# PIC32CX2051MTSH128S1 device description
Architecture: CORTEX-M4; Family: PIC32CXMT; Series: PIC32CXMTSH
Registers are 32-bit, read-write, no defined reset value unless marked. A register's access mark holds for its fields unless they carry their own. Offsets are from the block's base; [hi:lo] are bit positions; lines under a group give offsets from that group; {n}, {i} and the like mark numbered series; 'fields as' and 'values as' point back to an identical list.

## PWM — Pulse Width Modulation Controller
Instances: PWM 0x4801C000
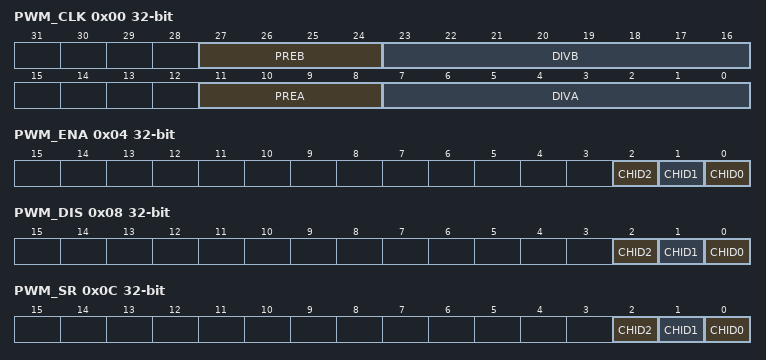
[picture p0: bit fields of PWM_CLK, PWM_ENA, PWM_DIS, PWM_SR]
0x00 PWM_CLK — PWM Clock Register
  [27:24] PREB — CLKB Source Clock Selection
    0=CLK (Peripheral clock); 1=CLK_DIV2 (Peripheral clock/2); 2=CLK_DIV4 (Peripheral clock/4); 3=CLK_DIV8 (Peripheral clock/8); 4=CLK_DIV16 (Peripheral clock/16); 5=CLK_DIV32 (Peripheral clock/32); 6=CLK_DIV64 (Peripheral clock/64); 7=CLK_DIV128 (Peripheral clock/128); 8=CLK_DIV256 (Peripheral clock/256); 9=CLK_DIV512 (Peripheral clock/512); 10=CLK_DIV1024 (Peripheral clock/1024)
  [23:16] DIVB — CLKB Divide Factor
    0=CLKB_POFF (CLKB clock is turned off); 1=PREB (CLKB clock is clock selected by PREB)
  [11:8] PREA — CLKA Source Clock Selection
    values as PREB
  [7:0] DIVA — CLKA Divide Factor
    0=CLKA_POFF (CLKA clock is turned off); 1=PREA (CLKA clock is clock selected by PREA)
0x04 PWM_ENA wo — PWM Enable Register
  [2] CHID2 — Channel ID
  [1] CHID1 — Channel ID
  [0] CHID0 — Channel ID
0x08 PWM_DIS wo — PWM Disable Register
  fields as PWM_ENA
0x0C PWM_SR ro — PWM Status Register
  fields as PWM_ENA
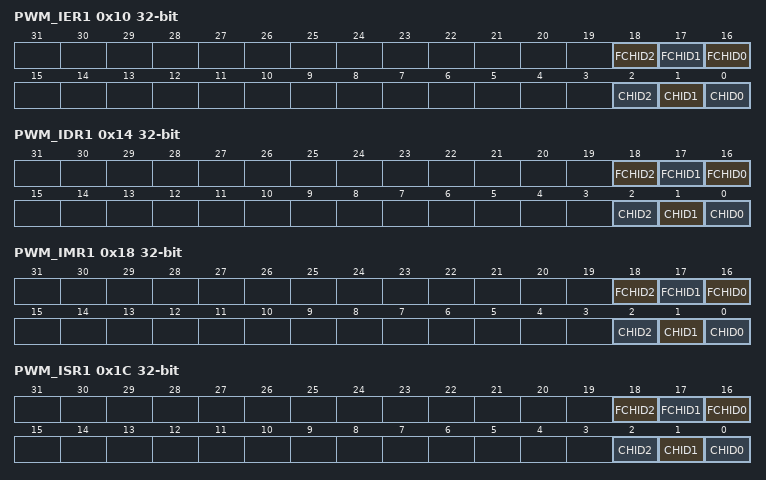
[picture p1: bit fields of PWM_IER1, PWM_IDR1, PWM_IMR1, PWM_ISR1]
0x10 PWM_IER1 wo — PWM Interrupt Enable Register 1
  [18] FCHID2 — Fault Protection Trigger on Channel 2 Interrupt Enable
  [17] FCHID1 — Fault Protection Trigger on Channel 1 Interrupt Enable
  [16] FCHID0 — Fault Protection Trigger on Channel 0 Interrupt Enable
  [2] CHID2 — Counter Event on Channel 2 Interrupt Enable
  [1] CHID1 — Counter Event on Channel 1 Interrupt Enable
  [0] CHID0 — Counter Event on Channel 0 Interrupt Enable
0x14 PWM_IDR1 wo — PWM Interrupt Disable Register 1
  [18] FCHID2 — Fault Protection Trigger on Channel 2 Interrupt Disable
  [17] FCHID1 — Fault Protection Trigger on Channel 1 Interrupt Disable
  [16] FCHID0 — Fault Protection Trigger on Channel 0 Interrupt Disable
  [2] CHID2 — Counter Event on Channel 2 Interrupt Disable
  [1] CHID1 — Counter Event on Channel 1 Interrupt Disable
  [0] CHID0 — Counter Event on Channel 0 Interrupt Disable
0x18 PWM_IMR1 ro — PWM Interrupt Mask Register 1
  [18] FCHID2 — Fault Protection Trigger on Channel 2 Interrupt Mask
  [17] FCHID1 — Fault Protection Trigger on Channel 1 Interrupt Mask
  [16] FCHID0 — Fault Protection Trigger on Channel 0 Interrupt Mask
  [2] CHID2 — Counter Event on Channel 2 Interrupt Mask
  [1] CHID1 — Counter Event on Channel 1 Interrupt Mask
  [0] CHID0 — Counter Event on Channel 0 Interrupt Mask
0x1C PWM_ISR1 ro — PWM Interrupt Status Register 1
  [18] FCHID2 — Fault Protection Trigger on Channel 2
  [17] FCHID1 — Fault Protection Trigger on Channel 1
  [16] FCHID0 — Fault Protection Trigger on Channel 0
  [2] CHID2 — Counter Event on Channel 2
  [1] CHID1 — Counter Event on Channel 1
  [0] CHID0 — Counter Event on Channel 0
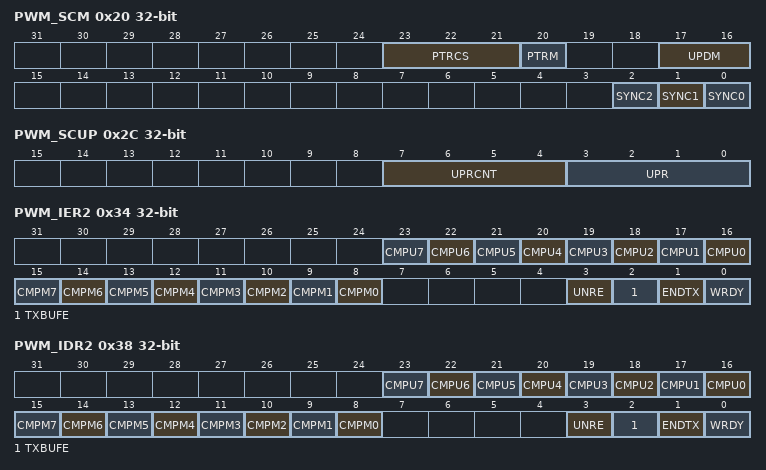
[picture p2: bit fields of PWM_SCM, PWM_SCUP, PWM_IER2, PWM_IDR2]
0x20 PWM_SCM — PWM Sync Channels Mode Register
  [23:21] PTRCS — Peripheral DMA Controller Transfer Request Comparison Selection
  [20] PTRM — Peripheral DMA Controller Transfer Request Mode
  [17:16] UPDM — Synchronous Channels Update Mode
    0=MODE0 (Manual write of double buffer registers and manual update of synchronous channels); 1=MODE1 (Manual write of double buffer registers and automatic update of synchronous channels); 2=MODE2 (Automatic write of duty-cycle update registers by the Peripheral DMA Controller and automatic update of synchronous channels)
  [2] SYNC2 — Synchronous Channel 2
  [1] SYNC1 — Synchronous Channel 1
  [0] SYNC0 — Synchronous Channel 0
0x28 PWM_SCUC — PWM Sync Channels Update Control Register
  [0] UPDULOCK — Synchronous Channels Update Unlock
0x2C PWM_SCUP — PWM Sync Channels Update Period Register
  [7:4] UPRCNT — Update Period Counter
  [3:0] UPR — Update Period
0x30 PWM_SCUPUPD wo — PWM Sync Channels Update Period Update Register
  [3:0] UPRUPD — Update Period Update
0x34 PWM_IER2 wo — PWM Interrupt Enable Register 2
  [n+16] CMPU{n} (n=0..7) — Comparison {n} Update Interrupt Enable
  [n+8] CMPM{n} (n=0..7) — Comparison {n} Match Interrupt Enable
  [3] UNRE — Synchronous Channels Update Underrun Error Interrupt Enable
  [2] TXBUFE — PDC TX Buffer Empty Interrupt Enable
  [1] ENDTX — PDC End of TX Buffer Interrupt Enable
  [0] WRDY — Write Ready for Synchronous Channels Update Interrupt Enable
0x38 PWM_IDR2 wo — PWM Interrupt Disable Register 2
  [n+16] CMPU{n} (n=0..7) — Comparison {n} Update Interrupt Disable
  [n+8] CMPM{n} (n=0..7) — Comparison {n} Match Interrupt Disable
  [3] UNRE — Synchronous Channels Update Underrun Error Interrupt Disable
  [2] TXBUFE — PDC TX Buffer Empty Interrupt Disable
  [1] ENDTX — PDC End of TX Buffer Interrupt Disable
  [0] WRDY — Write Ready for Synchronous Channels Update Interrupt Disable
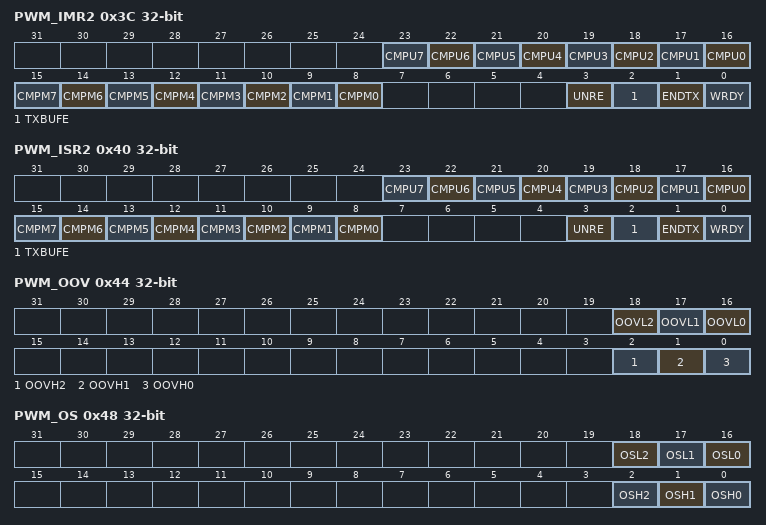
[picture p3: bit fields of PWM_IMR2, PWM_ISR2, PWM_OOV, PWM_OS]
0x3C PWM_IMR2 ro — PWM Interrupt Mask Register 2
  [n+16] CMPU{n} (n=0..7) — Comparison {n} Update Interrupt Mask
  [n+8] CMPM{n} (n=0..7) — Comparison {n} Match Interrupt Mask
  [3] UNRE — Synchronous Channels Update Underrun Error Interrupt Mask
  [2] TXBUFE — PDC TX Buffer Empty Interrupt Mask
  [1] ENDTX — PDC End of TX Buffer Interrupt Mask
  [0] WRDY — Write Ready for Synchronous Channels Update Interrupt Mask
0x40 PWM_ISR2 ro — PWM Interrupt Status Register 2
  [n+16] CMPU{n} (n=0..7) — Comparison {n} Update
  [n+8] CMPM{n} (n=0..7) — Comparison {n} Match
  [3] UNRE — Synchronous Channels Update Underrun Error
  [2] TXBUFE — PDC TX Buffer Empty
  [1] ENDTX — PDC End of TX Buffer
  [0] WRDY — Write Ready for Synchronous Channels Update
0x44 PWM_OOV — PWM Output Override Value Register
  [18] OOVL2 — Output Override Value for PWML output of the channel 2
  [17] OOVL1 — Output Override Value for PWML output of the channel 1
  [16] OOVL0 — Output Override Value for PWML output of the channel 0
  [2] OOVH2 — Output Override Value for PWMH output of the channel 2
  [1] OOVH1 — Output Override Value for PWMH output of the channel 1
  [0] OOVH0 — Output Override Value for PWMH output of the channel 0
0x48 PWM_OS — PWM Output Selection Register
  [18] OSL2 — Output Selection for PWML output of the channel 2
  [17] OSL1 — Output Selection for PWML output of the channel 1
  [16] OSL0 — Output Selection for PWML output of the channel 0
  [2] OSH2 — Output Selection for PWMH output of the channel 2
  [1] OSH1 — Output Selection for PWMH output of the channel 1
  [0] OSH0 — Output Selection for PWMH output of the channel 0
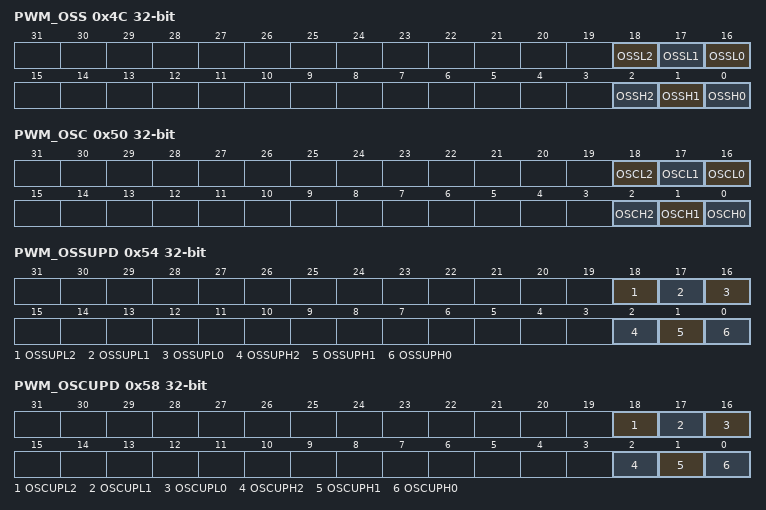
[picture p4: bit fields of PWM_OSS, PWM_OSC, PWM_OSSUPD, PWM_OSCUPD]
0x4C PWM_OSS wo — PWM Output Selection Set Register
  [18] OSSL2 — Output Selection Set for PWML output of the channel 2
  [17] OSSL1 — Output Selection Set for PWML output of the channel 1
  [16] OSSL0 — Output Selection Set for PWML output of the channel 0
  [2] OSSH2 — Output Selection Set for PWMH output of the channel 2
  [1] OSSH1 — Output Selection Set for PWMH output of the channel 1
  [0] OSSH0 — Output Selection Set for PWMH output of the channel 0
0x50 PWM_OSC wo — PWM Output Selection Clear Register
  [18] OSCL2 — Output Selection Clear for PWML output of the channel 2
  [17] OSCL1 — Output Selection Clear for PWML output of the channel 1
  [16] OSCL0 — Output Selection Clear for PWML output of the channel 0
  [2] OSCH2 — Output Selection Clear for PWMH output of the channel 2
  [1] OSCH1 — Output Selection Clear for PWMH output of the channel 1
  [0] OSCH0 — Output Selection Clear for PWMH output of the channel 0
0x54 PWM_OSSUPD wo — PWM Output Selection Set Update Register
  [18] OSSUPL2 — Output Selection Set for PWML output of the channel 2
  [17] OSSUPL1 — Output Selection Set for PWML output of the channel 1
  [16] OSSUPL0 — Output Selection Set for PWML output of the channel 0
  [2] OSSUPH2 — Output Selection Set for PWMH output of the channel 2
  [1] OSSUPH1 — Output Selection Set for PWMH output of the channel 1
  [0] OSSUPH0 — Output Selection Set for PWMH output of the channel 0
0x58 PWM_OSCUPD wo — PWM Output Selection Clear Update Register
  [18] OSCUPL2 — Output Selection Clear for PWML output of the channel 2
  [17] OSCUPL1 — Output Selection Clear for PWML output of the channel 1
  [16] OSCUPL0 — Output Selection Clear for PWML output of the channel 0
  [2] OSCUPH2 — Output Selection Clear for PWMH output of the channel 2
  [1] OSCUPH1 — Output Selection Clear for PWMH output of the channel 1
  [0] OSCUPH0 — Output Selection Clear for PWMH output of the channel 0
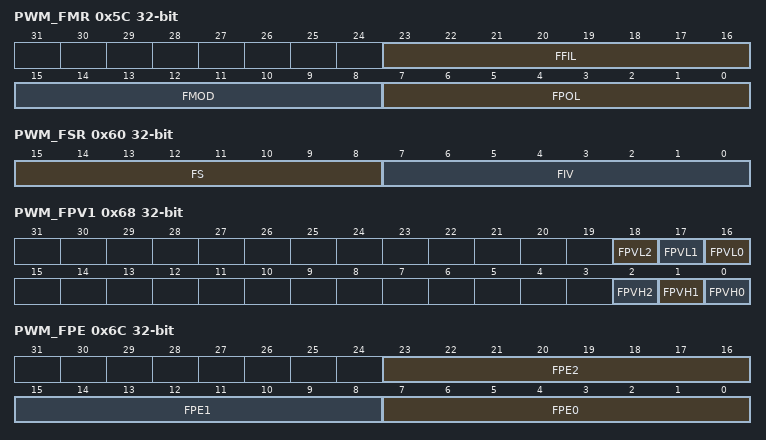
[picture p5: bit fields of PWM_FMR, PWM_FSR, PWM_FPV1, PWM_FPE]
0x5C PWM_FMR — PWM Fault Mode Register
  [23:16] FFIL — Fault Filtering
  [15:8] FMOD — Fault Activation Mode
  [7:0] FPOL — Fault Polarity
0x60 PWM_FSR ro — PWM Fault Status Register
  [15:8] FS — Fault Status
  [7:0] FIV — Fault Input Value
0x64 PWM_FCR wo — PWM Fault Clear Register
  [7:0] FCLR — Fault Clear
0x68 PWM_FPV1 — PWM Fault Protection Value Register 1
  [18] FPVL2 — Fault Protection Value for PWML output on channel 2
  [17] FPVL1 — Fault Protection Value for PWML output on channel 1
  [16] FPVL0 — Fault Protection Value for PWML output on channel 0
  [2] FPVH2 — Fault Protection Value for PWMH output on channel 2
  [1] FPVH1 — Fault Protection Value for PWMH output on channel 1
  [0] FPVH0 — Fault Protection Value for PWMH output on channel 0
0x6C PWM_FPE — PWM Fault Protection Enable Register
  [23:16] FPE2 — Fault Protection Enable for channel 2
  [15:8] FPE1 — Fault Protection Enable for channel 1
  [7:0] FPE0 — Fault Protection Enable for channel 0
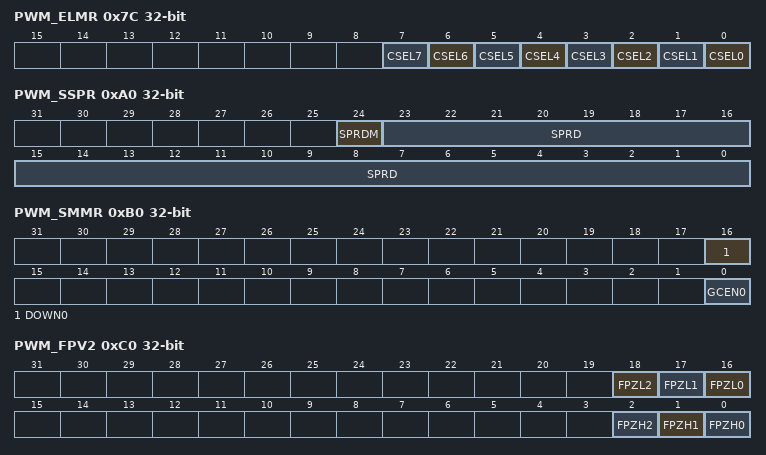
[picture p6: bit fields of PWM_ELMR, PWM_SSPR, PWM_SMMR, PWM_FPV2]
0x7C PWM_ELMR — PWM Event Line 0 Mode Register
  [n] CSEL{n} (n=0..7) — Comparison {n} Selection
0xA0 PWM_SSPR — PWM Spread Spectrum Register
  [24] SPRDM — Spread Spectrum Counter Mode
  [23:0] SPRD — Spread Spectrum Limit Value
0xA4 PWM_SSPUP wo — PWM Spread Spectrum Update Register
  [23:0] SPRDUP — Spread Spectrum Limit Value Update
0xAC PWM_DEBUG — Debug Register
  [0] OUTMODE — PWM Output Mode when System is in Debug Mode
    0=NO_EFFECT (Keeps the PWM outputs running when the processor reports a debug operating mode.)
0xB0 PWM_SMMR — PWM Stepper Motor Mode Register
  [16] DOWN0 — Down Count
  [0] GCEN0 — Gray Count Enable
0xC0 PWM_FPV2 — PWM Fault Protection Value 2 Register
  [18] FPZL2 — Fault Protection to Hi-Z for PWML output on channel 2
  [17] FPZL1 — Fault Protection to Hi-Z for PWML output on channel 1
  [16] FPZL0 — Fault Protection to Hi-Z for PWML output on channel 0
  [2] FPZH2 — Fault Protection to Hi-Z for PWMH output on channel 2
  [1] FPZH1 — Fault Protection to Hi-Z for PWMH output on channel 1
  [0] FPZH0 — Fault Protection to Hi-Z for PWMH output on channel 0
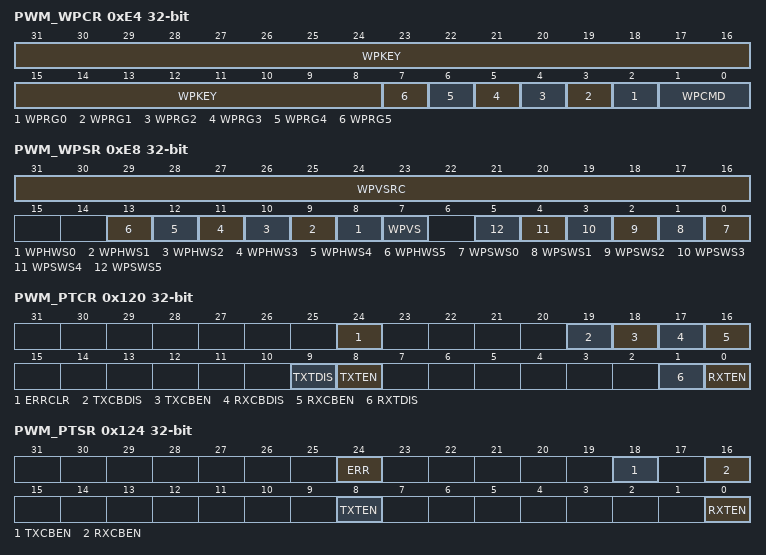
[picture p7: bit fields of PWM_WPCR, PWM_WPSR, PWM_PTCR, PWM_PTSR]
0xE4 PWM_WPCR wo — PWM Write Protection Control Register
  [31:8] WPKEY — Write Protection Key
    0x50574D=PASSWD (Writing any other value in this field aborts the write operation of the WPCMD field. Always reads as 0)
  [n+2] WPRG{n} (n=0..5) — Write Protection Register Group {n}
  [1:0] WPCMD — Write Protection Command
    0=DISABLE_SW_PROT (Disables the software write protection of the register groups of which the bit WPRGx is at '1'.); 1=ENABLE_SW_PROT (Enables the software write protection of the register groups of which the bit WPRGx is at '1'.); 2=ENABLE_HW_PROT (Enables the hardware write protection of the register groups of which the bit WPRGx is at '1'. Only a hardware reset of the PWM controller can disable the hardware write protection. Moreover, to meet security requirements, the PIO lines associated with the PWM can not be configured through the PIO interface.)
0xE8 PWM_WPSR ro — PWM Write Protection Status Register
  [31:16] WPVSRC — Write Protect Violation Source
  [n+8] WPHWS{n} (n=0..5) — Write Protect HW Status
  [7] WPVS — Write Protect Violation Status
  [n] WPSWS{n} (n=0..5) — Write Protect SW Status
0x108 PWM_TPR — Transmit Pointer Register
  [31:0] TXPTR — Transmit Counter Register
0x10C PWM_TCR — Transmit Counter Register
  [15:0] TXCTR
0x118 PWM_TNPR — Transmit Next Pointer Register
  [31:0] TXNPTR — Transmit Next Pointer
0x11C PWM_TNCR — Transmit Next Counter Register
  [15:0] TXNCTR — Transmit Counter Next
0x120 PWM_PTCR wo — Transfer Control Register
  [24] ERRCLR — Transfer Bus Error Clear
  [19] TXCBDIS — Transmitter Circular Buffer Disable
  [18] TXCBEN — Transmitter Circular Buffer Enable
  [17] RXCBDIS — Receiver Circular Buffer Disable
  [16] RXCBEN — Receiver Circular Buffer Enable
  [9] TXTDIS — Transmitter Transfer Disable
  [8] TXTEN — Transmitter Transfer Enable
  [1] RXTDIS — Receiver Transfer Disable
  [0] RXTEN — Receiver Transfer Enable
0x124 PWM_PTSR ro — Transfer Status Register
  [24] ERR — Transfer Bus Error
  [18] TXCBEN — Transmitter Circular Buffer Enable
  [16] RXCBEN — Receiver Circular Buffer Enable
  [8] TXTEN — Transmitter Transfer Enable
  [0] RXTEN — Receiver Transfer Enable
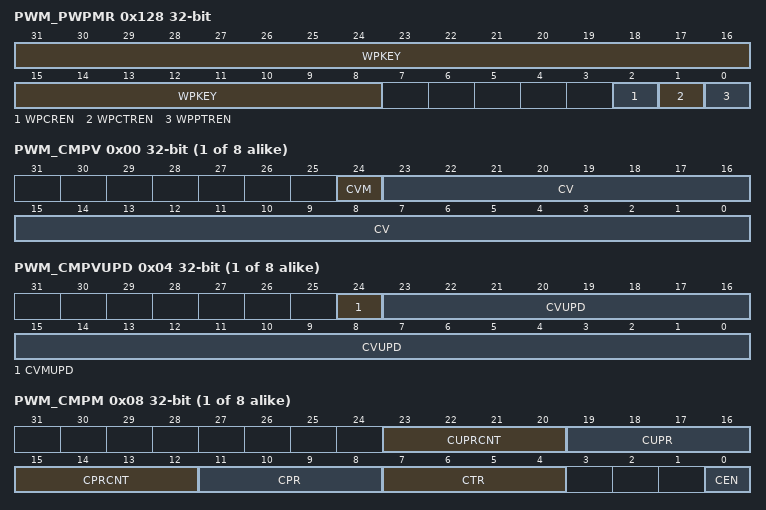
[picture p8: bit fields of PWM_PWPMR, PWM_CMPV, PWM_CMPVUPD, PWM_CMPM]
0x128 PWM_PWPMR — Write Protection Mode Register
  [31:8] WPKEY — Write Protection Key
    0x504443=PASSWD (Writing any other value in this field aborts the write operation. Always reads as 0.)
  [2] WPCREN — Write Protection Control Register Enable
  [1] WPCTREN — Write Protection Counter Registers Enable
  [0] WPPTREN — Write Protection Pointer Registers Enable
{0x130+0x10*i} PWM_CMP[{i}] (i=0..7) group
  0x00 PWM_CMPV — PWM Comparison 0 Value Register
    [24] CVM — Comparison x Value Mode
      0=COMPARE_AT_INCREMENT (Compare when counter is incrementing); 1=COMPARE_AT_DECREMENT (Compare when counter is decrementing)
    [23:0] CV — Comparison x Value
  0x04 PWM_CMPVUPD wo — PWM Comparison 0 Value Update Register
    [24] CVMUPD — Comparison x Value Mode Update
    [23:0] CVUPD — Comparison x Value Update
  0x08 PWM_CMPM — PWM Comparison 0 Mode Register
    [23:20] CUPRCNT — Comparison x Update Period Counter
    [19:16] CUPR — Comparison x Update Period
    [15:12] CPRCNT — Comparison x Period Counter
    [11:8] CPR — Comparison x Period
    [7:4] CTR — Comparison x Trigger
    [0] CEN — Comparison x Enable
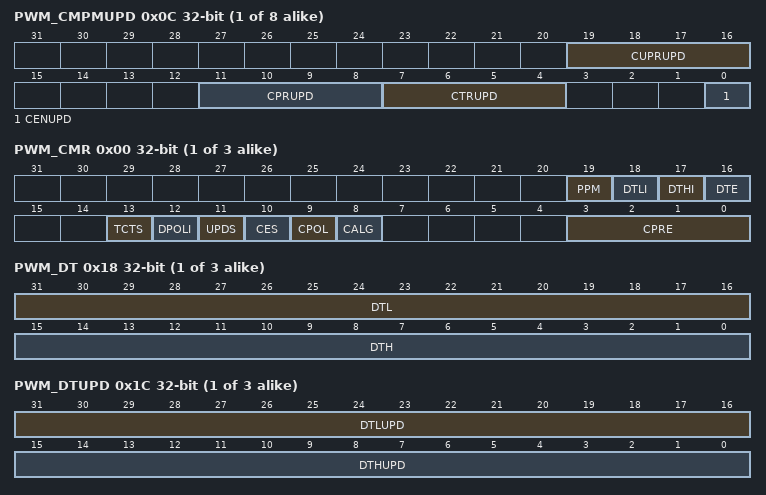
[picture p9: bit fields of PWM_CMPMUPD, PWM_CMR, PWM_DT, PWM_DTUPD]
  0x0C PWM_CMPMUPD wo — PWM Comparison 0 Mode Update Register
    [19:16] CUPRUPD — Comparison x Update Period Update
    [11:8] CPRUPD — Comparison x Period Update
    [7:4] CTRUPD — Comparison x Trigger Update
    [0] CENUPD — Comparison x Enable Update
{0x200+0x20*i} PWM_CH_NUM[{i}] (i=0..2) group
  0x00 PWM_CMR — PWM Channel Mode Register
    [19] PPM — Push-Pull Mode
    [18] DTLI — Dead-Time PWMLx Output Inverted
    [17] DTHI — Dead-Time PWMHx Output Inverted
    [16] DTE — Dead-Time Generator Enable
    [13] TCTS — Timer Counter Trigger Selection
    [12] DPOLI — Disabled Polarity Inverted
    [11] UPDS — Update Selection
      0=UPDATE_AT_PERIOD (At the next end of PWM period); 1=UPDATE_AT_HALF_PERIOD (At the next end of Half PWM period)
    [10] CES — Counter Event Selection
      0=SINGLE_EVENT (At the end of PWM period); 1=DOUBLE_EVENT (At half of PWM period AND at the end of PWM period)
    [9] CPOL — Channel Polarity
      0=LOW_POLARITY (Waveform starts at low level); 1=HIGH_POLARITY (Waveform starts at high level)
    [8] CALG — Channel Alignment
      0=LEFT_ALIGNED; 1=CENTER_ALIGNED
    [3:0] CPRE — Channel Prescaler
      0=MCK (Peripheral clock); 1=MCK_DIV_2 (Peripheral clock/2); 2=MCK_DIV_4 (Peripheral clock/4); 3=MCK_DIV_8 (Peripheral clock/8); 4=MCK_DIV_16 (Peripheral clock/16); 5=MCK_DIV_32 (Peripheral clock/32); 6=MCK_DIV_64 (Peripheral clock/64); 7=MCK_DIV_128 (Peripheral clock/128); 8=MCK_DIV_256 (Peripheral clock/256); 9=MCK_DIV_512 (Peripheral clock/512); 10=MCK_DIV_1024 (Peripheral clock/1024); 11=CLKA (Clock A); 12=CLKB (Clock B)
  0x04 PWM_CDTY — PWM Channel Duty Cycle Register
    [23:0] CDTY — Channel Duty-Cycle
  0x08 PWM_CDTYUPD wo — PWM Channel Duty Cycle Update Register
    [23:0] CDTYUPD — Channel Duty-Cycle Update
  0x0C PWM_CPRD — PWM Channel Period Register
    [23:0] CPRD — Channel Period
  0x10 PWM_CPRDUPD wo — PWM Channel Period Update Register
    [23:0] CPRDUPD — Channel Period Update
  0x14 PWM_CCNT ro — PWM Channel Counter Register
    [23:0] CNT — Channel Counter Register
  0x18 PWM_DT — PWM Channel Dead Time Register
    [31:16] DTL — Dead-Time Value for PWMLx Output
    [15:0] DTH — Dead-Time Value for PWMHx Output
  0x1C PWM_DTUPD wo — PWM Channel Dead Time Update Register
    [31:16] DTLUPD — Dead-Time Value Update for PWMLx Output
    [15:0] DTHUPD — Dead-Time Value Update for PWMHx Output
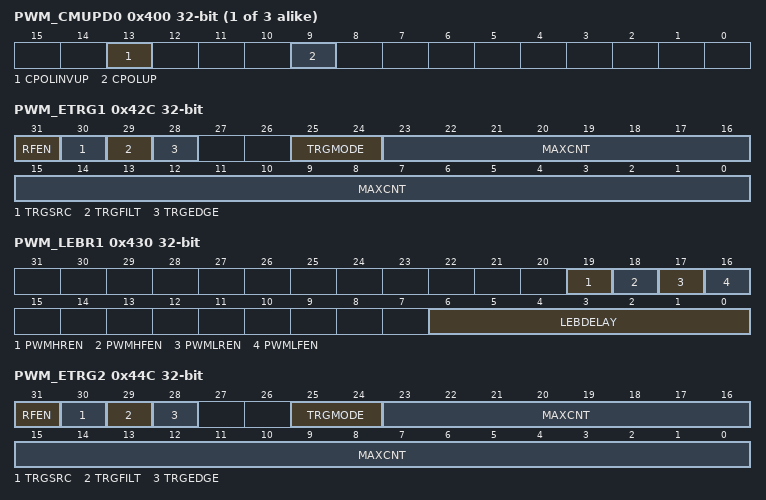
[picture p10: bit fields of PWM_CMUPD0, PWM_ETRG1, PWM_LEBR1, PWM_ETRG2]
{0x400+0x20*i} PWM_CMUPD{i} wo (i=0..2) — PWM Channel Mode Update Register (ch_num = {i})
  [13] CPOLINVUP — Channel Polarity Inversion Update
  [9] CPOLUP — Channel Polarity Update
0x42C PWM_ETRG1 — PWM External Trigger Register 1
  [31] RFEN — Recoverable Fault Enable
  [30] TRGSRC — Trigger Source
  [29] TRGFILT — Filtered input
  [28] TRGEDGE — Edge Selection
    0=FALLING_ZERO (TRGMODE = 1: TRGINx event detection on falling edge. TRGMODE = 2, 3: TRGINx active level is 0); 1=RISING_ONE (TRGMODE = 1: TRGINx event detection on rising edge. TRGMODE = 2, 3: TRGINx active level is 1)
  [25:24] TRGMODE — External Trigger Mode
    0=OFF (External trigger is not enabled.); 1=MODE1 (External PWM Reset Mode); 2=MODE2 (External PWM Start Mode); 3=MODE3 (Cycle-by-cycle Duty Mode)
  [23:0] MAXCNT — Maximum Counter value
0x430 PWM_LEBR1 — PWM Leading-Edge Blanking Register 1
  [19] PWMHREN — PWMH Rising Edge Enable
  [18] PWMHFEN — PWMH Falling Edge Enable
  [17] PWMLREN — PWML Rising Edge Enable
  [16] PWMLFEN — PWML Falling Edge Enable
  [6:0] LEBDELAY — Leading-Edge Blanking Delay for TRGINx
0x44C PWM_ETRG2 — PWM External Trigger Register 2
  fields as PWM_ETRG1
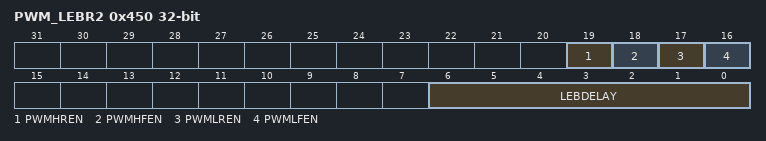
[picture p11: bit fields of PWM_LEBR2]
0x450 PWM_LEBR2 — PWM Leading-Edge Blanking Register 2
  fields as PWM_LEBR1
